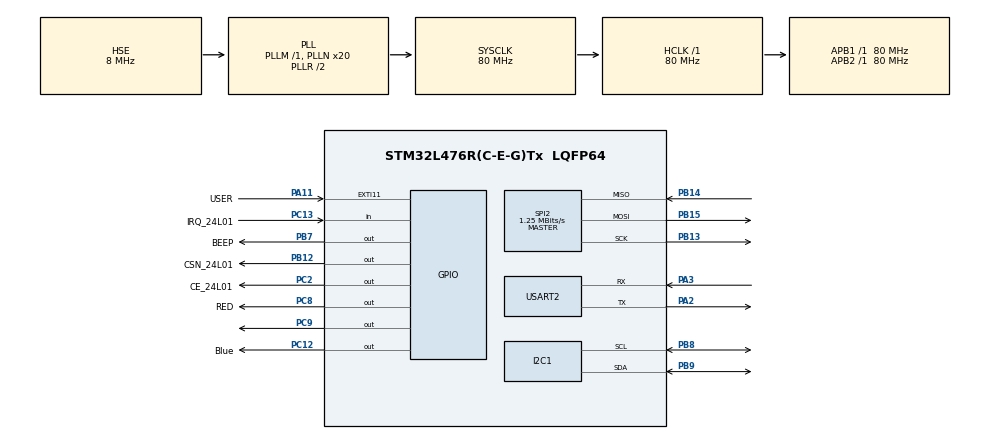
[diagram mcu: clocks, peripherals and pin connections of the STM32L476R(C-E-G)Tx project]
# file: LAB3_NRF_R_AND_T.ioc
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I2C1.Timing=0x10909CEC
Mcu.Family=STM32L4
Mcu.Name=STM32L476R(C-E-G)Tx
Mcu.Package=LQFP64
NVIC.EXTI15_10_IRQn=true\:4\:0\:true\:false\:true\:true\:true\:true
NVIC.PriorityGroup=NVIC_PRIORITYGROUP_4
NVIC.TIM2_IRQn=true\:0\:0\:false\:false\:true\:true\:true\:true
PA11.GPIO_Label=USER
PA11.Signal=GPXTI11
PA13\ (JTMS-SWDIO).Mode=Serial_Wire
PA13\ (JTMS-SWDIO).Signal=SYS_JTMS-SWDIO
PA14\ (JTCK-SWCLK).Mode=Serial_Wire
PA14\ (JTCK-SWCLK).Signal=SYS_JTCK-SWCLK
PA2.Mode=Asynchronous
PA2.Signal=USART2_TX
PA3.Mode=Asynchronous
PA3.Signal=USART2_RX
PB12.GPIO_Label=CSN_24L01
PB12.GPIO_Speed=GPIO_SPEED_FREQ_VERY_HIGH
PB12.Signal=GPIO_Output
PB13.Mode=Full_Duplex_Master
PB13.Signal=SPI2_SCK
PB14.Mode=Full_Duplex_Master
PB14.Signal=SPI2_MISO
PB15.Mode=Full_Duplex_Master
PB15.Signal=SPI2_MOSI
PB7.GPIO_Label=BEEP
PB7.GPIO_Speed=GPIO_SPEED_FREQ_VERY_HIGH
PB7.Signal=GPIO_Output
PB8.Mode=I2C
PB8.Signal=I2C1_SCL
PB9.Mode=I2C
PB9.Signal=I2C1_SDA
PC12.GPIO_Label=Blue
PC12.GPIO_Speed=GPIO_SPEED_FREQ_HIGH
PC12.PinState=GPIO_PIN_SET
PC12.Signal=GPIO_Output
PC13.GPIO_Label=IRQ_24L01
PC13.Signal=GPIO_Input
PC2.GPIO_Label=CE_24L01
PC2.GPIO_Speed=GPIO_SPEED_FREQ_VERY_HIGH
PC2.Signal=GPIO_Output
PC8.GPIO_Label=RED
PC8.GPIO_Speed=GPIO_SPEED_FREQ_HIGH
PC8.PinState=GPIO_PIN_SET
PC8.Signal=GPIO_Output
PC9.Signal=GPIO_Output
PH0-OSC_IN\ (PH0).Mode=HSE-External-Oscillator
PH0-OSC_IN\ (PH0).Signal=RCC_OSC_IN
PH1-OSC_OUT\ (PH1).Mode=HSE-External-Oscillator
PH1-OSC_OUT\ (PH1).Signal=RCC_OSC_OUT
ProjectManager.HeapSize=0x200
ProjectManager.StackSize=0x400
ProjectManager.TargetToolchain=STM32CubeIDE
RCC.ADCFreq_Value=32000000
RCC.AHBFreq_Value=80000000
RCC.APB1Freq_Value=80000000
RCC.APB1TimFreq_Value=80000000
RCC.APB2Freq_Value=80000000
RCC.APB2TimFreq_Value=80000000
RCC.CortexFreq_Value=80000000
RCC.HCLKFreq_Value=80000000
RCC.HSE_VALUE=8000000
RCC.HSI_VALUE=16000000
RCC.LSE_VALUE=32768
RCC.MSI_VALUE=4000000
RCC.PLLN=20
RCC.PLLSourceVirtual=RCC_PLLSOURCE_HSE
RCC.SYSCLKFreq_VALUE=80000000
RCC.SYSCLKSource=RCC_SYSCLKSOURCE_PLLCLK
RCC.USBFreq_Value=32000000
RCC.VCOOutputFreq_Value=160000000
SPI2.BaudRatePrescaler=SPI_BAUDRATEPRESCALER_64
SPI2.CalculateBaudRate=1.25 MBits/s
SPI2.Direction=SPI_DIRECTION_2LINES
SPI2.Mode=SPI_MODE_MASTER
SPI2.VirtualType=VM_MASTER
TIM2.CounterMode=TIM_COUNTERMODE_DOWN
TIM2.Period=2
TIM2.Prescaler=79
USART2.VirtualMode-Asynchronous=VM_ASYNC
VP_TIM2_VS_ClockSourceINT.Mode=Internal
board=custom

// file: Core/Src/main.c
/* USER CODE BEGIN Header */
/**
  ******************************************************************************
  * @file           : main.c
  * @brief          : Main program body
  ******************************************************************************
  * @attention
  *
  * Copyright (c) 2023 STMicroelectronics.
  * All rights reserved.
  *
  * This software is licensed under terms that can be found in the LICENSE file
  * in the root directory of this software component.
  * If no LICENSE file comes with this software, it is provided AS-IS.
  *
  ******************************************************************************
  */
/* USER CODE END Header */
#include "main.h"
#include "i2c.h"
#include "spi.h"
#include "tim.h"
#include "usart.h"
#include "gpio.h"

/* USER CODE BEGIN Includes */
#include "Si24R1.h"
#include "NRF24l01.h"
/* USER CODE END Includes */

void SystemClock_Config(void);

/* USER CODE BEGIN 0 */
uint8_t TX_BUF[]="Qy is Da Shuai Ge!\r\n";
/* USER CODE END 0 */

int main(void)
{

  /* MCU Configuration--------------------------------------------------------*/

  /* Reset of all peripherals, Initializes the Flash interface and the Systick. */
  HAL_Init();

  /* Configure the system clock */
  SystemClock_Config();

  /* Initialize all configured peripherals */
  MX_GPIO_Init();
  MX_TIM2_Init();
  MX_USART2_UART_Init();
  MX_I2C1_Init();
  MX_SPI2_Init();
  /* USER CODE BEGIN 2 */
  Tx_Init();
  /* USER CODE END 2 */

  /* Infinite loop */
  /* USER CODE BEGIN WHILE */
  while (1)
  {
	  Tx_loop(TX_BUF);
	  HAL_Delay(1000);
    /* USER CODE END WHILE */

  }
}

void SystemClock_Config(void)
{
  RCC_OscInitTypeDef RCC_OscInitStruct = {0};
  RCC_ClkInitTypeDef RCC_ClkInitStruct = {0};

  /** Configure the main internal regulator output voltage
  */
  if (HAL_PWREx_ControlVoltageScaling(PWR_REGULATOR_VOLTAGE_SCALE1) != HAL_OK)
  {
    Error_Handler();
  }

  /** Initializes the RCC Oscillators according to the specified parameters
  * in the RCC_OscInitTypeDef structure.
  */
  RCC_OscInitStruct.OscillatorType = RCC_OSCILLATORTYPE_HSE;
  RCC_OscInitStruct.HSEState = RCC_HSE_ON;
  RCC_OscInitStruct.PLL.PLLState = RCC_PLL_ON;
  RCC_OscInitStruct.PLL.PLLSource = RCC_PLLSOURCE_HSE;
  RCC_OscInitStruct.PLL.PLLM = 1;
  RCC_OscInitStruct.PLL.PLLN = 20;
  RCC_OscInitStruct.PLL.PLLP = RCC_PLLP_DIV7;
  RCC_OscInitStruct.PLL.PLLQ = RCC_PLLQ_DIV2;
  RCC_OscInitStruct.PLL.PLLR = RCC_PLLR_DIV2;
  if (HAL_RCC_OscConfig(&RCC_OscInitStruct) != HAL_OK)
  {
    Error_Handler();
  }

  /** Initializes the CPU, AHB and APB buses clocks
  */
  RCC_ClkInitStruct.ClockType = RCC_CLOCKTYPE_HCLK|RCC_CLOCKTYPE_SYSCLK
                              |RCC_CLOCKTYPE_PCLK1|RCC_CLOCKTYPE_PCLK2;
  RCC_ClkInitStruct.SYSCLKSource = RCC_SYSCLKSOURCE_PLLCLK;
  RCC_ClkInitStruct.AHBCLKDivider = RCC_SYSCLK_DIV1;
  RCC_ClkInitStruct.APB1CLKDivider = RCC_HCLK_DIV1;
  RCC_ClkInitStruct.APB2CLKDivider = RCC_HCLK_DIV1;

  if (HAL_RCC_ClockConfig(&RCC_ClkInitStruct, FLASH_LATENCY_4) != HAL_OK)
  {
    Error_Handler();
  }
}

void Error_Handler(void)
{
  __disable_irq();
  while (1)
  {
  }
}
